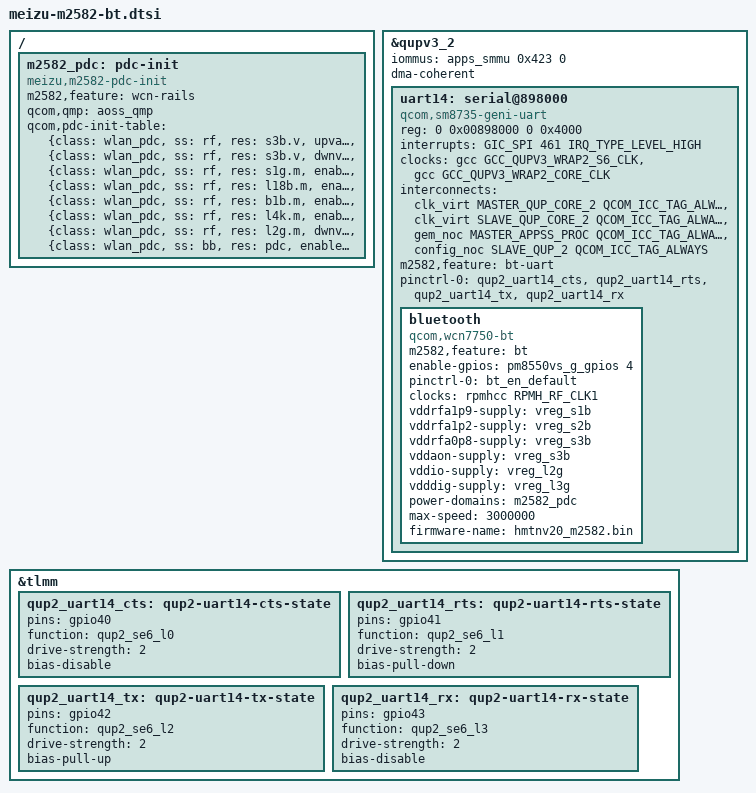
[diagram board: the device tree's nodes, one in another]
// SPDX-License-Identifier: BSD-3-Clause

/*
 * M2582 WCN7750: SE14 UART and PM8550VS-G GPIO4 enable.
 * Wiring, supply levels and PDC messages follow the factory runtime DT.
 */

#include <dt-bindings/clock/qcom,rpmh.h>
#include <dt-bindings/gpio/gpio.h>
#include <dt-bindings/interrupt-controller/arm-gic.h>
#include <dt-bindings/spmi/spmi.h>

&qupv3_2 {
	/* SE DMA maps buffers against the wrapper, with the factory stream ID. */

	iommus = <&apps_smmu 0x423 0>;
	dma-coherent;

	uart14: serial@898000 {
		compatible = "qcom,sm8735-geni-uart";
		reg = <0 0x00898000 0 0x4000>;
		interrupts = <GIC_SPI 461 IRQ_TYPE_LEVEL_HIGH>;
		clocks = <&gcc GCC_QUPV3_WRAP2_S6_CLK>,
			 <&gcc GCC_QUPV3_WRAP2_CORE_CLK>;
		clock-names = "se", "core";
		interconnects = <&clk_virt MASTER_QUP_CORE_2 QCOM_ICC_TAG_ALWAYS
				 &clk_virt SLAVE_QUP_CORE_2 QCOM_ICC_TAG_ALWAYS>,
				<&gem_noc MASTER_APPSS_PROC QCOM_ICC_TAG_ALWAYS
				 &config_noc SLAVE_QUP_2 QCOM_ICC_TAG_ALWAYS>;
		interconnect-names = "qup-core", "qup-config";
		status = "disabled";
	};
};

&tlmm {
	qup2_uart14_cts: qup2-uart14-cts-state {
		pins = "gpio40";
		function = "qup2_se6_l0";
		drive-strength = <2>;
		bias-disable;
	};

	qup2_uart14_rts: qup2-uart14-rts-state {
		pins = "gpio41";
		function = "qup2_se6_l1";
		drive-strength = <2>;
		bias-pull-down;
	};

	qup2_uart14_tx: qup2-uart14-tx-state {
		pins = "gpio42";
		function = "qup2_se6_l2";
		drive-strength = <2>;
		bias-pull-up;
	};

	qup2_uart14_rx: qup2-uart14-rx-state {
		pins = "gpio43";
		function = "qup2_se6_l3";
		drive-strength = <2>;
		bias-disable;
	};
};

&uart14 {
	status = "okay";

	m2582,feature = "bt-uart";

	pinctrl-names = "default";
	pinctrl-0 = <&qup2_uart14_cts>, <&qup2_uart14_rts>,
		    <&qup2_uart14_tx>, <&qup2_uart14_rx>;

	bluetooth {
		compatible = "qcom,wcn7750-bt";

		m2582,feature = "bt";

		enable-gpios = <&pm8550vs_g_gpios 4 GPIO_ACTIVE_HIGH>;

		pinctrl-names = "default";
		pinctrl-0 = <&bt_en_default>;

		/* The controller does not answer until its RF clock is voted on. */
		clocks = <&rpmhcc RPMH_RF_CLK1>;

		vddrfa1p9-supply = <&vreg_s1b>;
		vddrfa1p2-supply = <&vreg_s2b>;
		vddrfa0p8-supply = <&vreg_s3b>;
		vddaon-supply = <&vreg_s3b>;
		vddio-supply = <&vreg_l2g>;
		vdddig-supply = <&vreg_l3g>;

		/* Serdev attaches this domain before probing the Bluetooth client. */
		power-domains = <&m2582_pdc>;

		max-speed = <3000000>;
		firmware-name = "hmtnv20_m2582.bin";
	};
};

/* AOP WCN PDC setup; transport completion is checked by the provider. */
/ {
	m2582_pdc: pdc-init {
		compatible = "meizu,m2582-pdc-init";
		m2582,feature = "wcn-rails";

		qcom,qmp = <&aoss_qmp>;

		qcom,pdc-init-table =
			" {class: wlan_pdc, ss: rf, res: s3b.v, upval: 976}",
			" {class: wlan_pdc, ss: rf, res: s3b.v, dwnval: 616}",
			" {class: wlan_pdc, ss: rf, res: s1g.m, enable: 0}",
			" {class: wlan_pdc, ss: rf, res: l18b.m, enable: 0}",
			" {class: wlan_pdc, ss: rf, res: b1b.m, enable: 0}",
			" {class: wlan_pdc, ss: rf, res: l4k.m, enable: 0}",
			" {class: wlan_pdc, ss: rf, res: l2g.m, dwnval: 3}",
			" {class: wlan_pdc, ss: bb, res: pdc, enable: 1}";

		#power-domain-cells = <0>;
	};
};
